VERSION ""

NS_ :

BS_:

BU_: Ecu Gateway

VAL_TABLE_ GearTable 0 "Park" 1 "Reverse" 2 "Neutral" 3 "Drive" ;

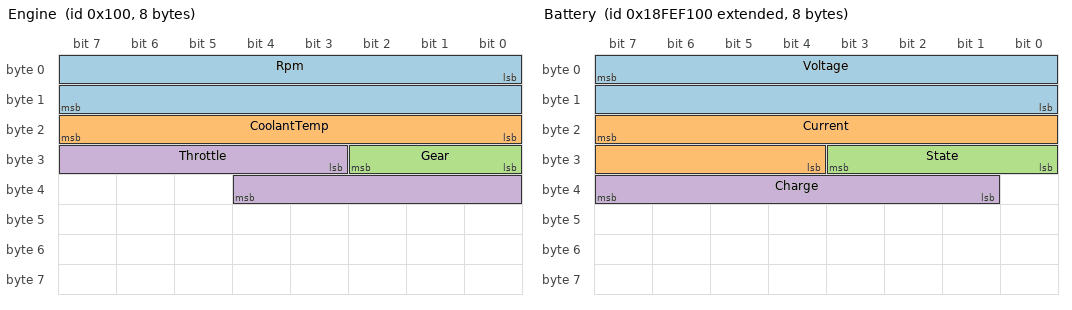
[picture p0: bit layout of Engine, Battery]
BO_ 256 Engine: 8 Ecu
 SG_ Rpm : 0|16@1+ (0.25,0) [0|16383.75] "rpm" Gateway
 SG_ CoolantTemp : 16|8@1- (1,-40) [-168|87] "degC" Gateway
 SG_ Gear : 24|3@1+ (1,0) [0|7] "" Gateway
 SG_ Throttle : 27|10@1+ (0.1,0) [0|102.3] "%" Gateway

BO_ 2566844672 Battery: 8 Ecu
 SG_ Voltage : 7|16@0+ (0.01,0) [0|655.35] "V" Gateway
 SG_ Current : 23|12@0- (0.1,0) [-204.8|204.7] "A" Gateway
 SG_ State : 27|4@0+ (1,0) [0|15] "" Gateway
 SG_ Charge : 39|7@0+ (1,0) [0|100] "%" Gateway

BO_ 512 Imu: 8 Ecu
 SG_ AccelX : 0|32@1- (1,0) [-100|100] "m/s^2" Gateway
 SG_ AccelY : 39|32@0- (1,0) [-100|100] "m/s^2" Gateway

BO_ 513 Position: 8 Ecu
 SG_ Latitude : 0|64@1- (1,0) [-90|90] "deg" Gateway

BO_ 2147484160 Bulk: 64 Ecu
 SG_ Sequence : 0|16@1+ (1,0) [0|65535] "" Gateway
 SG_ Checksum : 504|8@1+ (1,0) [0|255] "" Gateway

CM_ BO_ 256 "Engine status broadcast.";
BA_DEF_ BO_ "GenMsgCycleTime" INT 0 65535;
BA_DEF_ BO_ "VFrameFormat" ENUM "StandardCAN","ExtendedCAN","reserved","J1939PG","reserved","reserved","reserved","reserved","reserved","reserved","reserved","reserved","reserved","reserved","StandardCAN_FD","ExtendedCAN_FD";
BA_DEF_DEF_ "GenMsgCycleTime" 0;
BA_DEF_DEF_ "VFrameFormat" "StandardCAN";
BA_ "GenMsgCycleTime" BO_ 256 100;
BA_ "GenMsgCycleTime" BO_ 2566844672 1000;
BA_ "VFrameFormat" BO_ 2566844672 1;
BA_ "VFrameFormat" BO_ 2147484160 15;
VAL_ 256 Gear 0 "Park" 1 "Reverse" 2 "Neutral" 3 "Drive" ;
VAL_ 2566844672 State 0 "Idle" 1 "Charging" 2 "Discharging" 15 "Fault" ;
SIG_VALTYPE_ 512 AccelX : 1;
SIG_VALTYPE_ 512 AccelY : 1;
SIG_VALTYPE_ 513 Latitude : 2;
